# MSP430FR5962 register map
File version: 2.1
CPU: MSP430FR5962 r2p1, little endian, MPU, no FPU, 3 interrupt priority bits
Registers are 16-bit, read-write, reset 0x0 unless marked. A register's access mark holds for its fields unless they carry their own. Offsets are from the block's base; [hi:lo] are bit positions; {n}, {i} and the like mark numbered series.

## P7
Base 0x00000200
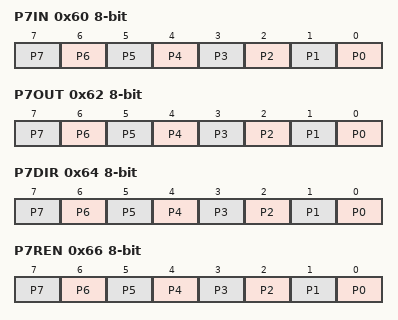
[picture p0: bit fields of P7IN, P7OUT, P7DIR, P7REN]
0x60 P7IN 8-bit — Port 7 Input
  [n] P{n} (n=0..7)
0x62 P7OUT 8-bit — Port 7 Output
  [n] P{n} (n=0..7)
0x64 P7DIR 8-bit — Port 7 Direction
  [n] P{n} (n=0..7)
0x66 P7REN 8-bit — Port 7 Resistor Enable
  [n] P{n} (n=0..7)
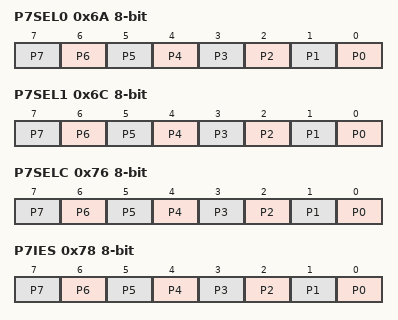
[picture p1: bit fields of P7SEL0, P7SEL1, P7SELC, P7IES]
0x6A P7SEL0 8-bit — Port 7 Select 0
  [n] P{n} (n=0..7)
0x6C P7SEL1 8-bit — Port 7 Select 1
  [n] P{n} (n=0..7)
0x6E P7IV — Port 7 Interrupt Vector Register
  [4:0] P7IV — [4:0] Port 7 interrupt vector value
    0=NONE (No interrupt pending); 2=P7IFG0 (Interrupt Source: Port 7.0 interrupt; Interrupt Flag: P7IFG0; Interrupt Priority: Highest); 4=P7IFG1 (Interrupt Source: Port 7.1 interrupt; Interrupt Flag: P7IFG1); 6=P7IFG2 (Interrupt Source: Port 7.2 interrupt; Interrupt Flag: P7IFG2); 8=P7IFG3 (Interrupt Source: Port 7.3 interrupt; Interrupt Flag: P7IFG3); 10=P7IFG4 (Interrupt Source: Port 7.4 interrupt; Interrupt Flag: P7IFG4); 12=P7IFG5 (Interrupt Source: Port 7.5 interrupt; Interrupt Flag: P7IFG5); 14=P7IFG6 (Interrupt Source: Port 7.6 interrupt; Interrupt Flag: P7IFG6); 16=P7IFG7 (Interrupt Source: Port 7.7 interrupt; Interrupt Flag: P7IFG7; Interrupt Priority: Lowest)
0x76 P7SELC 8-bit — Port 7 Complement Select
  [n] P{n} (n=0..7)
0x78 P7IES 8-bit — Port 7 Interrupt Edge Select
  [n] P{n} (n=0..7)
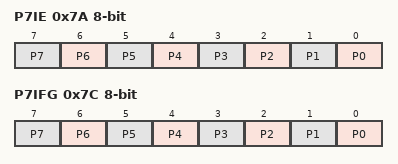
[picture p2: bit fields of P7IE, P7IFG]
0x7A P7IE 8-bit — Port 7 Interrupt Enable
  [n] P{n} (n=0..7)
0x7C P7IFG 8-bit — Port 7 Interrupt Flag
  [n] P{n} (n=0..7)

## P8
Base 0x00000200
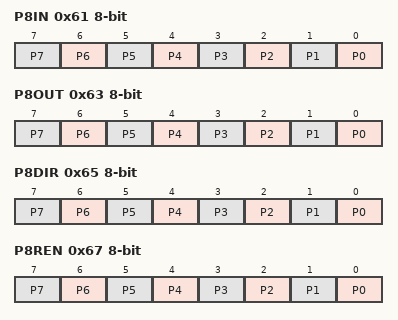
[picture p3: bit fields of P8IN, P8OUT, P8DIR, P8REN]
0x61 P8IN 8-bit — Port 8 Input
  [n] P{n} (n=0..7)
0x63 P8OUT 8-bit — Port 8 Output
  [n] P{n} (n=0..7)
0x65 P8DIR 8-bit — Port 8 Direction
  [n] P{n} (n=0..7)
0x67 P8REN 8-bit — Port 8 Resistor Enable
  [n] P{n} (n=0..7)
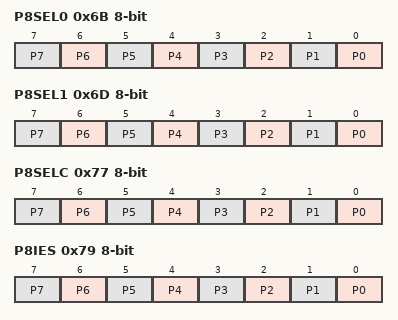
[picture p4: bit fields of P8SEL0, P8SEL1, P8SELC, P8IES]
0x6B P8SEL0 8-bit — Port 8 Select 0
  [n] P{n} (n=0..7)
0x6D P8SEL1 8-bit — Port 8 Select 1
  [n] P{n} (n=0..7)
0x77 P8SELC 8-bit — Port 8 Complement Select
  [n] P{n} (n=0..7)
0x79 P8IES 8-bit — Port 8 Interrupt Edge Select
  [n] P{n} (n=0..7)
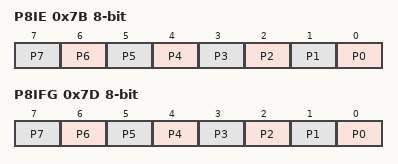
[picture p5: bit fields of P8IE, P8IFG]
0x7B P8IE 8-bit — Port 8 Interrupt Enable
  [n] P{n} (n=0..7)
0x7D P8IFG 8-bit — Port 8 Interrupt Flag
  [n] P{n} (n=0..7)
0x7E P8IV — Port 8 Interrupt Vector Register
  [4:0] P8IV — [4:0] Port 8 interrupt vector value
    0=NONE (No interrupt pending); 2=P8IFG0 (Interrupt Source: Port 8.0 interrupt; Interrupt Flag: P8IFG0; Interrupt Priority: Highest); 4=P8IFG1 (Interrupt Source: Port 8.1 interrupt; Interrupt Flag: P8IFG1); 6=P8IFG2 (Interrupt Source: Port 8.2 interrupt; Interrupt Flag: P8IFG2); 8=P8IFG3 (Interrupt Source: Port 8.3 interrupt; Interrupt Flag: P8IFG3); 10=P8IFG4 (Interrupt Source: Port 8.4 interrupt; Interrupt Flag: P8IFG4); 12=P8IFG5 (Interrupt Source: Port 8.5 interrupt; Interrupt Flag: P8IFG5); 14=P8IFG6 (Interrupt Source: Port 8.6 interrupt; Interrupt Flag: P8IFG6); 16=P8IFG7 (Interrupt Source: Port 8.7 interrupt; Interrupt Flag: P8IFG7; Interrupt Priority: Lowest)

## PE
Base 0x00000200
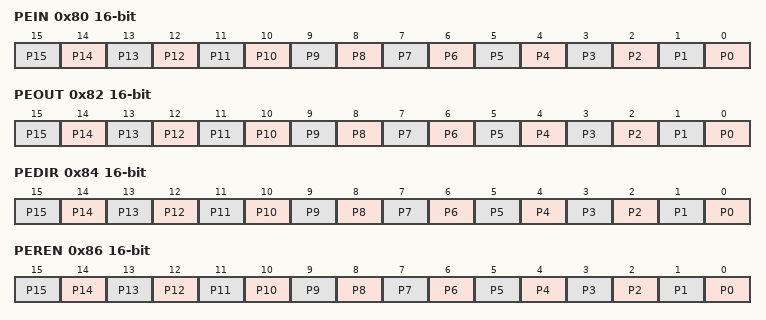
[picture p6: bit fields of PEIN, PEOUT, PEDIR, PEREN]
0x80 PEIN — Port E Input
  [n] P{n} (n=0..15)
0x82 PEOUT — Port E Output
  [n] P{n} (n=0..15)
0x84 PEDIR — Port E Direction
  [n] P{n} (n=0..15)
0x86 PEREN — Port E Resistor Enable
  [n] P{n} (n=0..15)
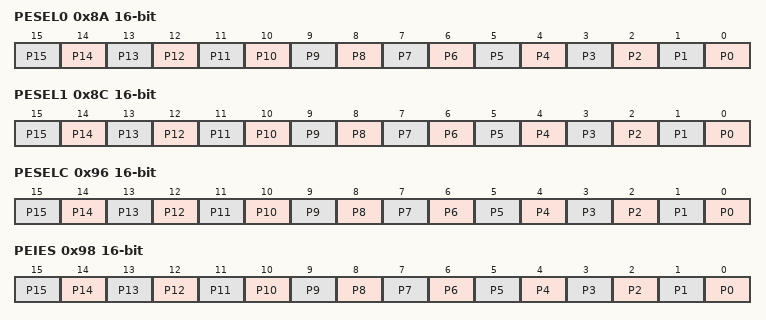
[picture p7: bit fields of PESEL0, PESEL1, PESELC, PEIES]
0x8A PESEL0 — Port E Select 0
  [n] P{n} (n=0..15)
0x8C PESEL1 — Port E Select 1
  [n] P{n} (n=0..15)
0x96 PESELC — Port E Complement Select
  [n] P{n} (n=0..15)
0x98 PEIES — Port E Interrupt Edge Select
  [n] P{n} (n=0..15)
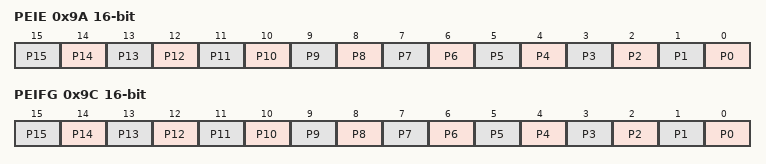
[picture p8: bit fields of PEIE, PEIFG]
0x9A PEIE — Port E Interrupt Enable
  [n] P{n} (n=0..15)
0x9C PEIFG — Port E Interrupt Flag
  [n] P{n} (n=0..15)

## P9
Base 0x00000200
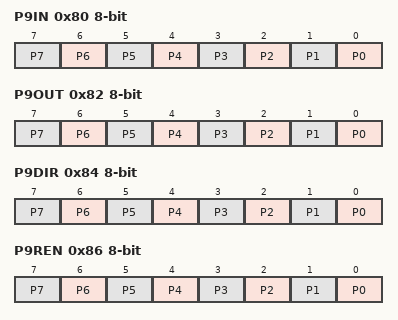
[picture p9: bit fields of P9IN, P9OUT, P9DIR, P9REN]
0x80 P9IN 8-bit — Port 9 Input
  [n] P{n} (n=0..7)
0x82 P9OUT 8-bit — Port 9 Output
  [n] P{n} (n=0..7)
0x84 P9DIR 8-bit — Port 9 Direction
  [n] P{n} (n=0..7)
0x86 P9REN 8-bit — Port 9 Resistor Enable
  [n] P{n} (n=0..7)
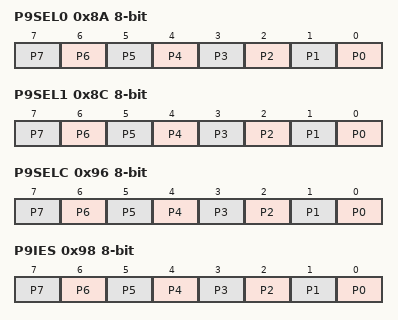
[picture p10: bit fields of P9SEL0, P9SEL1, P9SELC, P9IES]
0x8A P9SEL0 8-bit — Port 9 Select 0
  [n] P{n} (n=0..7)
0x8C P9SEL1 8-bit — Port 9 Select 1
  [n] P{n} (n=0..7)
0x8E P9IV — Port 9 Interrupt Vector Register
  [4:0] P9IV — [4:0] Port 9 interrupt vector value
    0=NONE (No interrupt pending); 2=P9IFG0 (Interrupt Source: Port 9.0 interrupt; Interrupt Flag: P9IFG0; Interrupt Priority: Highest); 4=P9IFG1 (Interrupt Source: Port 9.1 interrupt; Interrupt Flag: P9IFG1); 6=P9IFG2 (Interrupt Source: Port 9.2 interrupt; Interrupt Flag: P9IFG2); 8=P9IFG3 (Interrupt Source: Port 9.3 interrupt; Interrupt Flag: P9IFG3); 10=P9IFG4 (Interrupt Source: Port 9.4 interrupt; Interrupt Flag: P9IFG4); 12=P9IFG5 (Interrupt Source: Port 9.5 interrupt; Interrupt Flag: P9IFG5); 14=P9IFG6 (Interrupt Source: Port 9.6 interrupt; Interrupt Flag: P9IFG6); 16=P9IFG7 (Interrupt Source: Port 9.7 interrupt; Interrupt Flag: P9IFG7; Interrupt Priority: Lowest)
0x96 P9SELC 8-bit — Port 9 Complement Select
  [n] P{n} (n=0..7)
0x98 P9IES 8-bit — Port 9 Interrupt Edge Select
  [n] P{n} (n=0..7)
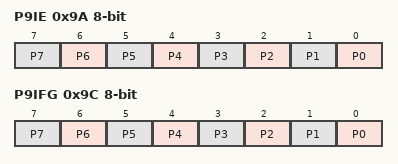
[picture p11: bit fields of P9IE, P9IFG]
0x9A P9IE 8-bit — Port 9 Interrupt Enable
  [n] P{n} (n=0..7)
0x9C P9IFG 8-bit — Port 9 Interrupt Flag
  [n] P{n} (n=0..7)
